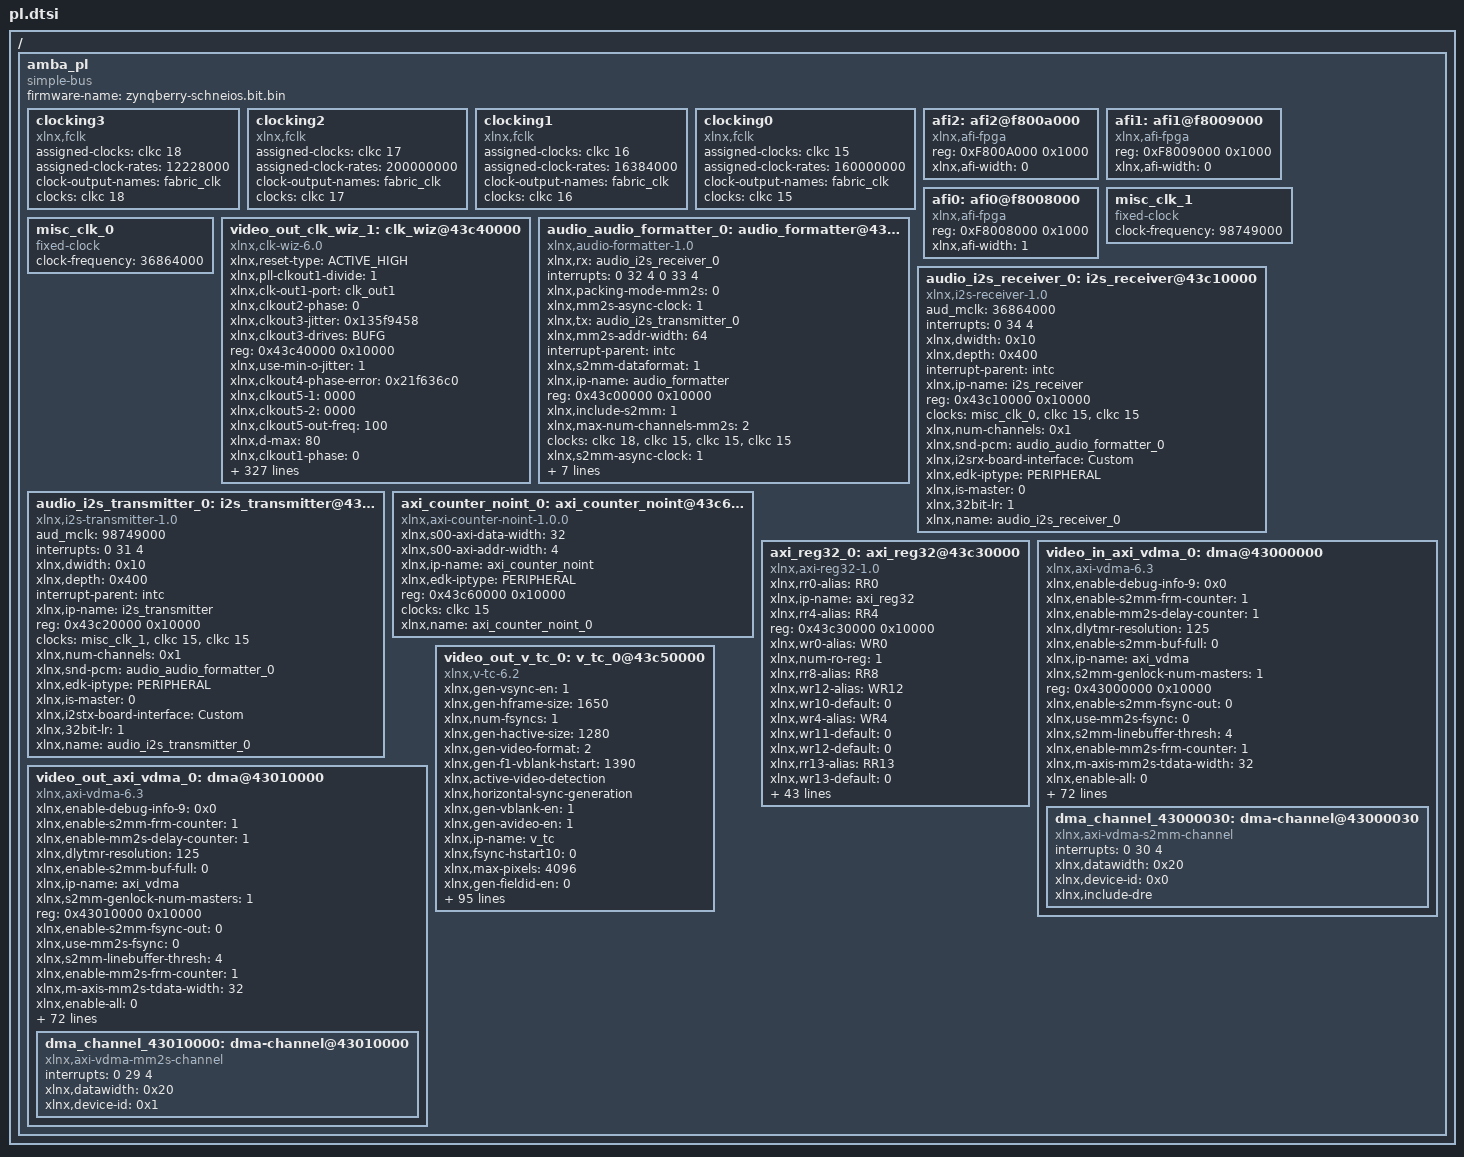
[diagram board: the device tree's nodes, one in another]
/ {
	amba_pl: amba_pl {
		ranges;
		compatible = "simple-bus";
		#address-cells = <1>;
		#size-cells = <1>;
		firmware-name = "zynqberry-schneios.bit.bin";
		clocking3: clocking3 {
			compatible = "xlnx,fclk";
			assigned-clocks = <&clkc 18>;
			assigned-clock-rates = <12228000>;
			#clock-cells = <0>;
			clock-output-names = "fabric_clk";
			clocks = <&clkc 18>;
		};
		clocking2: clocking2 {
			compatible = "xlnx,fclk";
			assigned-clocks = <&clkc 17>;
			assigned-clock-rates = <200000000>;
			#clock-cells = <0>;
			clock-output-names = "fabric_clk";
			clocks = <&clkc 17>;
		};
		clocking1: clocking1 {
			compatible = "xlnx,fclk";
			assigned-clocks = <&clkc 16>;
			assigned-clock-rates = <16384000>;
			#clock-cells = <0>;
			clock-output-names = "fabric_clk";
			clocks = <&clkc 16>;
		};
		clocking0: clocking0 {
			compatible = "xlnx,fclk";
			assigned-clocks = <&clkc 15>;
			assigned-clock-rates = <160000000>;
			#clock-cells = <0>;
			clock-output-names = "fabric_clk";
			clocks = <&clkc 15>;
		};
		afi2: afi2@f800a000 {
			status = "okay";
			compatible = "xlnx,afi-fpga";
			#address-cells = <1>;
			reg = <0xF800A000 0x1000>;
			#size-cells = <0>;
			xlnx,afi-width = <0>;
		};
		afi1: afi1@f8009000 {
			status = "okay";
			compatible = "xlnx,afi-fpga";
			#address-cells = <1>;
			reg = <0xF8009000 0x1000>;
			#size-cells = <0>;
			xlnx,afi-width = <0>;
		};
		afi0: afi0@f8008000 {
			status = "okay";
			compatible = "xlnx,afi-fpga";
			#address-cells = <1>;
			reg = <0xF8008000 0x1000>;
			#size-cells = <0>;
			xlnx,afi-width = <1>;
		};
		misc_clk_1: misc_clk_1 {
			compatible = "fixed-clock";
			clock-frequency = <98749000>;
			#clock-cells = <0>;
		};
		misc_clk_0: misc_clk_0 {
			compatible = "fixed-clock";
			clock-frequency = <36864000>;
			#clock-cells = <0>;
		};
		video_out_clk_wiz_1: clk_wiz@43c40000 {
			xlnx,reset-type = "ACTIVE_HIGH";
			xlnx,pll-clkout1-divide = <1>;
			xlnx,clk-out1-port = "clk_out1";
			xlnx,clkout2-phase = <0>;
			xlnx,clkout3-jitter = <0x135f9458>;
			xlnx,clkout3-drives = "BUFG";
			reg = <0x43c40000 0x10000>;
			xlnx,use-min-o-jitter = <1>;
			xlnx,clkout4-phase-error = <0x21f636c0>;
			xlnx,clkout5-1 = <0000>;
			xlnx,clkout5-2 = <0000>;
			xlnx,clkout5-out-freq = <100>;
			xlnx,d-max = <80>;
			xlnx,clkout1-phase = <0>;
			xlnx,divide6-auto = <0x186a0>;
			xlnx,clkout1-jitter = <0x13dd8e58>;
			xlnx,clkfb-in-n-port = "clkfb_in_n";
			xlnx,clkout2-requested-out-freq = <0x1620d350>;
			xlnx,use-locked = <1>;
			xlnx,pll-clkout5-duty-cycle = <0x7a120>;
			xlnx,mmcm-clkout3-use-fine-ps;
			xlnx,clkout1-drives = "BUFG";
			xlnx,input-clk-stopped-port = "input_clk_stopped";
			xlnx,clkout4-duty-cycle = <50>;
			xlnx,divide3-auto = <0x186a0>;
			xlnx,use-dyn-reconfig = <1>;
			xlnx,clkout3-actual-freq = <100>;
			xlnx,clkout6-requested-duty-cycle = <50>;
			xlnx,diff-clk-in1-board-interface = "Custom";
			xlnx,mmcm-clkout0-duty-cycle = <0x7a120>;
			xlnx,clkin2-jitter-ps = <100>;
			xlnx,clkout2-1 = <0000>;
			xlnx,in-freq-units = "Units_MHz";
			xlnx,clkout2-2 = <0000>;
			xlnx,feedback-source = "FDBK_AUTO";
			xlnx,clkout5-requested-out-freq = <100>;
			xlnx,name = "video_out_clk_wiz_1";
			xlnx,prim-in-freq = <200>;
			xlnx,mmcm-clkout5-divide = <1>;
			xlnx,clkout3-phase-error = <0x21f636c0>;
			xlnx,clk-in2-board-interface = "Custom";
			xlnx,clkin1-ui-jitter = <0x2710>;
			xlnx,use-inclk-switchover = <0>;
			clock-names = "clk_in1" , "s_axi_aclk";
			xlnx,clkout5-duty-cycle = <50>;
			xlnx,use-clkout4-bar = <0>;
			xlnx,mmcm-clkout1-duty-cycle = <0x7a120>;
			xlnx,mmcm-clkout2-use-fine-ps;
			xlnx,clkout2-out-freq = <0x1620d350>;
			xlnx,use-dyn-phase-shift = <0>;
			xlnx,mmcm-clkout3-divide = <1>;
			xlnx,clkout2-actual-freq = <100>;
			xlnx,o-min = <1>;
			xlnx,daddr-port = "daddr";
			xlnx,precision = <1>;
			xlnx,mmcm-ref-jitter1 = <0x2710>;
			clock-output-names = "0x43c40000-clk_out1 0x43c40000-clk_out2";
			xlnx,mmcm-ref-jitter2 = <0x2710>;
			xlnx,pll-notes = "No , notes";
			xlnx,use-phase-alignment = <1>;
			xlnx,ref-clk-freq = <100>;
			xlnx,clkout7-requested-duty-cycle = <50>;
			xlnx,inclk-sum-row0 = "Input , Clock , Freq , (MHz) , Input , Jitter , (UI)";
			xlnx,inclk-sum-row1 = "__primary_________200.000____________0.010";
			xlnx,use-fast-simulation = <0>;
			xlnx,inclk-sum-row2 = "no_secondary_input_clock";
			xlnx,mmcm-clkout1-divide = <2>;
			xlnx,din-port = "din";
			xlnx,reset-board-interface = "Custom";
			xlnx,clkout6-duty-cycle = <50>;
			xlnx,clkout2-phase-error = <0x134092d8>;
			xlnx,clkout1-requested-duty-cycle = <50>;
			xlnx,vco-max = <1200>;
			xlnx,use-freq-synth = <1>;
			xlnx,primtype-sel = "AUTO";
			xlnx,mmcm-clkout2-duty-cycle = <0x7a120>;
			xlnx,clkout5-used = <0>;
			xlnx,d-min = <1>;
			xlnx,pll-clkfbout-mult = <1>;
			xlnx,mmcm-clkout4-cascade;
			xlnx,use-clkout1-bar = <0>;
			xlnx,clk-out6-port = "clk_out6";
			xlnx,clkout2-sequence-number = <1>;
			xlnx,clk-valid-port = "CLK_VALID";
			xlnx,clkout2-used = <1>;
			xlnx,clkout4-sequence-number = <1>;
			xlnx,psincdec-port = "psincdec";
			xlnx,mmcm-clkout1-use-fine-ps;
			xlnx,clk-out3-port = "clk_out3";
			xlnx,clkout6-sequence-number = <1>;
			xlnx,platform = "UNKNOWN";
			xlnx,mmcm-clkout6-phase = <0>;
			xlnx,clkout1-actual-freq = <0x1620d350>;
			xlnx,clkout6-out-freq = <100>;
			xlnx,nr-outputs = <2>;
			xlnx,mmcm-clkin2-period = <10>;
			xlnx,prim-in-jitter = <0x2710>;
			xlnx,mmcm-clkfbout-mult-f = <0x2367b88>;
			status = "okay";
			xlnx,clkout6-1 = <0000>;
			xlnx,clkout6-2 = <0000>;
			xlnx,clkout7-duty-cycle = <50>;
			xlnx,outclk-sum-row1 = "clk_out1__74.25000______0.000______50.0______333.287____322.999";
			xlnx,outclk-sum-row2 = "clk_out2__371.25000______0.000______50.0______256.477____322.999";
			xlnx,jitter-sel = "Min_O_Jitter";
			xlnx,outclk-sum-row3 = "no_CLK_OUT3_output";
			xlnx,mmcm-clkout5-phase = <0>;
			xlnx,mmcm-clkout3-duty-cycle = <0x7a120>;
			xlnx,outclk-sum-row4 = "no_CLK_OUT4_output";
			xlnx,clkfb-in-p-port = "clkfb_in_p";
			xlnx,outclk-sum-row5 = "no_CLK_OUT5_output";
			xlnx,outclk-sum-row6 = "no_CLK_OUT6_output";
			xlnx,outclk-sum-row7 = "no_CLK_OUT7_output";
			xlnx,clkout1-phase-error = <0x134092d8>;
			xlnx,divide5-auto = <0x186a0>;
			xlnx,pll-bandwidth = "OPTIMIZED";
			xlnx,psdone-port = "psdone";
			xlnx,clkout3-1 = <0000>;
			xlnx,edk-iptype = "PERIPHERAL";
			xlnx,clkout3-2 = <0000>;
			xlnx,clkout3-requested-out-freq = <100>;
			xlnx,pll-clkout4-divide = <1>;
			xlnx,pll-clkfbout-phase = <0>;
			xlnx,divide2-auto = <0x30d40>;
			xlnx,override-mmcm = <0>;
			xlnx,clkout6-jitter = <0>;
			xlnx,ss-mode = "CENTER_HIGH";
			xlnx,mmcm-notes = "None";
			xlnx,clkout6-drives = "BUFG";
			xlnx,mmcm-clkfbout-use-fine-ps;
			xlnx,mmcm-clkout0-use-fine-ps;
			xlnx,ss-mod-period = <4000>;
			xlnx,mmcm-clkout4-phase = <0>;
			xlnx,clkout2-requested-duty-cycle = <50>;
			xlnx,clkout0-actual-freq = <0x46cf710>;
			xlnx,divclk = <0000>;
			xlnx,primary-port = "clk_in1";
			xlnx,mmcm-compensation = "ZHOLD";
			xlnx,clkout6-requested-out-freq = <100>;
			xlnx,clkout0-1 = <0000>;
			xlnx,clkout0-2 = <0000>;
			xlnx,clkout2-requested-phase = <0>;
			xlnx,relative-inclk = "REL_PRIMARY";
			xlnx,pll-clkout2-divide = <1>;
			xlnx,clkout4-requested-phase = <0>;
			xlnx,enable-user-clock0 = <0>;
			xlnx,filter-1 = <0000>;
			xlnx,mmcm-clkout4-duty-cycle = <0x7a120>;
			xlnx,clkout3-out-freq = <100>;
			xlnx,clkout4-jitter = <0x15490920>;
			xlnx,clkout6-requested-phase = <0>;
			xlnx,clkoutphy-requested-freq = <600>;
			xlnx,enable-user-clock1 = <0>;
			xlnx,filter-2 = <0000>;
			xlnx,ss-mod-freq = <250>;
			xlnx,in-jitter-units = "Units_UI";
			xlnx,mmcm-divclk-divide = <10>;
			xlnx,enable-user-clock2 = <0>;
			xlnx,enable-user-clock3 = <0>;
			xlnx,lock-1 = <0000>;
			xlnx,clkout4-drives = "BUFG";
			xlnx,lock-2 = <0000>;
			xlnx,den-port = "den";
			xlnx,lock-3 = <0000>;
			xlnx,use-safe-clock-startup = <0>;
			xlnx,mmcm-clkout3-phase = <0>;
			xlnx,dwe-port = "dwe";
			xlnx,clkfb-out-n-port = "clkfb_out_n";
			xlnx,use-max-i-jitter = <0>;
			xlnx,drdy-port = "drdy";
			xlnx,vco-min = <600>;
			xlnx,pll-clkout0-divide = <1>;
			xlnx,clkin1-jitter-ps = <50>;
			xlnx,clk-in-sel-port = "clk_in_sel";
			xlnx,use-freeze = <0>;
			xlnx,clkout2-jitter = <0xf498747>;
			xlnx,enable-pll0 = <0>;
			xlnx,enable-pll1 = <0>;
			xlnx,clkout2-drives = "BUFG";
			xlnx,use-inclk-stopped = <0>;
			xlnx,use-clkout3-bar = <0>;
			xlnx,use-clk-valid = <0>;
			xlnx,mmcm-clkout2-phase = <0>;
			compatible = "xlnx,clk-wiz-6.0" , "xlnx,clocking-wizard";
			xlnx,reset-port = "reset";
			xlnx,mmcm-clkout5-duty-cycle = <0x7a120>;
			xlnx,mmcm-clkout0-divide-f = <10>;
			xlnx,pll-clkout0-duty-cycle = <0x7a120>;
			xlnx,speed-grade = <1>;
			xlnx,diff-clk-in2-board-interface = "Custom";
			xlnx,clkout3-requested-duty-cycle = <50>;
			xlnx,use-status = <0>;
			xlnx,prim-source = "Single_ended_clock_capable_pin";
			xlnx,clkout7-used = <0>;
			xlnx,use-clkfb-stopped = <0>;
			xlnx,mmcm-clkout1-phase = <0>;
			xlnx,mmcm-clkout6-divide = <1>;
			xlnx,clkout7-out-freq = <100>;
			xlnx,prim-in-timeperiod = <10>;
			xlnx,clkout4-used = <0>;
			xlnx,pll-clkin-period = <1>;
			xlnx,clk-out5-port = "clk_out5";
			xlnx,psclk-port = "psclk";
			xlnx,primitive = "MMCM";
			xlnx,clkout1-used;
			xlnx,reset-low = <0>;
			xlnx,clk-in1-board-interface = "Custom";
			xlnx,clk-out2-port = "clk_out2";
			xlnx,power-down-port = "power_down";
			xlnx,clkout7-phase-error = <0>;
			xlnx,mmcm-clkout6-duty-cycle = <0x7a120>;
			xlnx,mmcm-clkout4-divide = <1>;
			xlnx,mmcm-clkfbout-phase = <0>;
			xlnx,mmcm-clkout0-phase = <0>;
			xlnx,pll-clkout1-duty-cycle = <0x7a120>;
			xlnx,user-clk-freq0 = <100>;
			xlnx,user-clk-freq1 = <100>;
			xlnx,pll-clkout5-phase = <0>;
			xlnx,user-clk-freq2 = <100>;
			xlnx,secondary-in-jitter = <0x2710>;
			xlnx,user-clk-freq3 = <100>;
			xlnx,use-clock-sequencing = <0>;
			xlnx,secondary-source = "Single_ended_clock_capable_pin";
			xlnx,cddcdone-port = "cddcdone";
			xlnx,clkout7-phase = <0>;
			xlnx,psen-port = "psen";
			xlnx,mmcm-clkout6-use-fine-ps;
			xlnx,dclk-port = "dclk";
			xlnx,m-max = <64>;
			xlnx,outclk-sum-row0a = "Output , Output , Phase , Duty , Cycle , Pk-to-Pk , Phase";
			xlnx,clkout1-requested-out-freq = <0x46cf710>;
			xlnx,clkout6-actual-freq = <100>;
			xlnx,divide7-auto = <0x186a0>;
			xlnx,outclk-sum-row0b = "Clock , Freq , (MHz) , (degrees) , (%) , Jitter , (ps) , Error , (ps)";
			xlnx,clkout4-1 = <0000>;
			xlnx,locked-port = "locked";
			xlnx,clkin2-ui-jitter = <0x2710>;
			xlnx,clkout4-2 = <0000>;
			xlnx,enable-clock-monitor = <0>;
			xlnx,mmcm-clkout2-divide = <1>;
			xlnx,ss-mod-time = <0xfa0>;
			xlnx,auto-primitive = "MMCM";
			xlnx,divide4-auto = <0x186a0>;
			xlnx,pll-clkout4-phase = <0>;
			xlnx,use-power-down = <0>;
			xlnx,mmcm-startup-wait;
			xlnx,divide1-auto = <1>;
			xlnx,clkout4-requested-duty-cycle = <50>;
			xlnx,clkout4-requested-out-freq = <100>;
			xlnx,optimize-clocking-structure-en = <0>;
			xlnx,clkout4-out-freq = <100>;
			xlnx,clkout6-phase = <0>;
			xlnx,num-out-clks = <2>;
			xlnx,ip-name = "clk_wiz";
			xlnx,pll-clkout2-duty-cycle = <0x7a120>;
			xlnx,clkout1-1 = <0000>;
			xlnx,clkout1-2 = <0000>;
			xlnx,clkout1-duty-cycle = <50>;
			xlnx,pll-divclk-divide = <1>;
			xlnx,clkout6-phase-error = <0>;
			xlnx,dout-port = "dout";
			xlnx,clkout1-sequence-number = <1>;
			xlnx,pll-clkout3-phase = <0>;
			xlnx,cddcreq-port = "cddcreq";
			xlnx,clkout7-requested-out-freq = <100>;
			xlnx,use-spread-spectrum = <0>;
			xlnx,clkout3-sequence-number = <1>;
			xlnx,clkout5-sequence-number = <1>;
			xlnx,summary-strings = "empty";
			xlnx,pll-compensation = "SYSTEM_SYNCHRONOUS";
			xlnx,clkout5-phase = <0>;
			xlnx,clkout7-sequence-number = <1>;
			xlnx,status-port = "STATUS";
			xlnx,clkfb-out-p-port = "clkfb_out_p";
			xlnx,mmcm-clkout5-use-fine-ps;
			xlnx,clkfb-in-port = "clkfb_in";
			xlnx,clkout5-actual-freq = <100>;
			xlnx,input-mode = "frequency";
			xlnx,interface-selection = <1>;
			xlnx,mmcm-bandwidth = "HIGH";
			xlnx,calc-done = "empty";
			xlnx,pll-clkout2-phase = <0>;
			xlnx,has-cddc = <0>;
			xlnx,power-reg = <0000>;
			xlnx,mmcm-clkin1-period = <5>;
			xlnx,pll-clkout3-duty-cycle = <0x7a120>;
			xlnx,clkout2-duty-cycle = <50>;
			xlnx,clkout4-phase = <0>;
			xlnx,pll-clkout5-divide = <1>;
			xlnx,clkout7-jitter = <0>;
			clocks = <&clkc 17>, <&clkc 15>;
			xlnx,clkout1-out-freq = <0x46cf710>;
			xlnx,clkout7-drives = "BUFG";
			xlnx,clkout5-phase-error = <0>;
			xlnx,pll-clkout1-phase = <0>;
			xlnx,clkout5-requested-duty-cycle = <50>;
			xlnx,clkfb-in-signaling = "SINGLE";
			xlnx,enable-clkoutphy = <0>;
			xlnx,use-clkout2-bar = <0>;
			xlnx,secondary-port = "clk_in2";
			xlnx,clkout3-phase = <0>;
			xlnx,pll-clkout3-divide = <1>;
			xlnx,use-reset = <1>;
			xlnx,override-pll = <0>;
			xlnx,clkoutphy-mode = "VCO";
			xlnx,mmcm-clkout4-use-fine-ps;
			xlnx,clkout5-jitter = <0>;
			xlnx,clkout6-used = <0>;
			xlnx,m-min = <2>;
			xlnx,mmcm-clock-hold;
			xlnx,clkfb-stopped-port = "clkfb_stopped";
			xlnx,clk-out7-port = "clk_out7";
			xlnx,clkout1-requested-phase = <0>;
			xlnx,clkout4-actual-freq = <100>;
			xlnx,pll-clk-feedback = "CLKFBOUT";
			xlnx,phaseshift-mode = "WAVEFORM";
			xlnx,clkfb-out-port = "clkfb_out";
			xlnx,clkout5-drives = "BUFG";
			xlnx,o-max = <128>;
			xlnx,clkout3-requested-phase = <0>;
			xlnx,jitter-options = "UI";
			xlnx,secondary-in-timeperiod = <10>;
			xlnx,pll-clkout4-duty-cycle = <0x7a120>;
			xlnx,clkout3-used = <0>;
			xlnx,clkout5-requested-phase = <0>;
			xlnx,pll-clkout0-phase = <0>;
			xlnx,clk-out4-port = "clk_out4";
			xlnx,clkout3-duty-cycle = <50>;
			xlnx,clkout7-requested-phase = <0>;
			xlnx,secondary-in-freq = <100>;
			xlnx,use-min-power = <0>;
			xlnx,clkfbout-1 = <0000>;
			#clock-cells = <1>;
			xlnx,pll-ref-jitter = <0x2710>;
			xlnx,clkfbout-2 = <0000>;
			xlnx,component-name = "zsys_clk_wiz_1_0";
		};
		audio_audio_formatter_0: audio_formatter@43c00000 {
			xlnx,rx = <&audio_i2s_receiver_0>;
			interrupts = < 0 32 4 0 33 4 >;
			compatible = "xlnx,audio-formatter-1.0" , "xlnx,audio-formatter-1.0";
			xlnx,packing-mode-mm2s = <0>;
			xlnx,mm2s-async-clock = <1>;
			xlnx,tx = <&audio_i2s_transmitter_0>;
			xlnx,mm2s-addr-width = <64>;
			interrupt-parent = <&intc>;
			xlnx,s2mm-dataformat = <1>;
			xlnx,ip-name = "audio_formatter";
			reg = <0x43c00000 0x10000>;
			xlnx,include-s2mm = <1>;
			xlnx,max-num-channels-mm2s = <2>;
			clocks = <&clkc 18>, <&clkc 15>, <&clkc 15>, <&clkc 15>;
			xlnx,s2mm-async-clock = <1>;
			xlnx,packing-mode-s2mm = <0>;
			xlnx,edk-iptype = "PERIPHERAL";
			xlnx,s2mm-addr-width = <64>;
			status = "okay";
			clock-names = "aud_mclk" , "m_axis_mm2s_aclk" , "s_axi_lite_aclk" , "s_axis_s2mm_aclk";
			xlnx,mm2s-dataformat = <3>;
			interrupt-names = "irq_mm2s" , "irq_s2mm";
			xlnx,include-mm2s = <1>;
			xlnx,max-num-channels-s2mm = <2>;
			xlnx,name = "audio_audio_formatter_0";
		};
		audio_i2s_receiver_0: i2s_receiver@43c10000 {
			aud_mclk = <36864000>;
			interrupts = < 0 34 4 >;
			compatible = "xlnx,i2s-receiver-1.0" , "xlnx,i2s-receiver-1.0";
			xlnx,dwidth = <0x10>;
			xlnx,depth = <0x400>;
			interrupt-parent = <&intc>;
			xlnx,ip-name = "i2s_receiver";
			reg = <0x43c10000 0x10000>;
			clocks = <&misc_clk_0>, <&clkc 15>, <&clkc 15>;
			xlnx,num-channels = <0x1>;
			xlnx,snd-pcm = <&audio_audio_formatter_0>;
			xlnx,i2srx-board-interface = "Custom";
			xlnx,edk-iptype = "PERIPHERAL";
			xlnx,is-master = <0>;
			status = "okay";
			clock-names = "aud_mclk" , "m_axis_aud_aclk" , "s_axi_ctrl_aclk";
			xlnx,32bit-lr = <1>;
			interrupt-names = "irq";
			xlnx,name = "audio_i2s_receiver_0";
		};
		audio_i2s_transmitter_0: i2s_transmitter@43c20000 {
			aud_mclk = <98749000>;
			interrupts = < 0 31 4 >;
			compatible = "xlnx,i2s-transmitter-1.0" , "xlnx,i2s-transmitter-1.0";
			xlnx,dwidth = <0x10>;
			xlnx,depth = <0x400>;
			interrupt-parent = <&intc>;
			xlnx,ip-name = "i2s_transmitter";
			reg = <0x43c20000 0x10000>;
			clocks = <&misc_clk_1>, <&clkc 15>, <&clkc 15>;
			xlnx,num-channels = <0x1>;
			xlnx,snd-pcm = <&audio_audio_formatter_0>;
			xlnx,edk-iptype = "PERIPHERAL";
			xlnx,is-master = <0>;
			xlnx,i2stx-board-interface = "Custom";
			status = "okay";
			clock-names = "aud_mclk" , "s_axi_ctrl_aclk" , "s_axis_aud_aclk";
			xlnx,32bit-lr = <1>;
			interrupt-names = "irq";
			xlnx,name = "audio_i2s_transmitter_0";
		};
		axi_counter_noint_0: axi_counter_noint@43c60000 {
			xlnx,s00-axi-data-width = <32>;
			compatible = "xlnx,axi-counter-noint-1.0.0";
			status = "okay";
			clock-names = "s00_axi_aclk";
			xlnx,s00-axi-addr-width = <4>;
			xlnx,ip-name = "axi_counter_noint";
			xlnx,edk-iptype = "PERIPHERAL";
			reg = <0x43c60000 0x10000>;
			clocks = <&clkc 15>;
			xlnx,name = "axi_counter_noint_0";
		};
		axi_reg32_0: axi_reg32@43c30000 {
			xlnx,rr0-alias = "RR0";
			xlnx,ip-name = "axi_reg32";
			xlnx,rr4-alias = "RR4";
			reg = <0x43c30000 0x10000>;
			xlnx,wr0-alias = "WR0";
			xlnx,num-ro-reg = <1>;
			xlnx,rr8-alias = "RR8";
			xlnx,wr12-alias = "WR12";
			xlnx,wr10-default = <0>;
			xlnx,wr4-alias = "WR4";
			xlnx,wr11-default = <0>;
			xlnx,wr12-default = <0>;
			xlnx,rr13-alias = "RR13";
			xlnx,wr13-default = <0>;
			xlnx,wr8-alias = "WR8";
			xlnx,wr14-default = <0>;
			xlnx,wr15-default = <0>;
			compatible = "xlnx,axi-reg32-1.0";
			xlnx,rr3-alias = "RR3";
			xlnx,rr7-alias = "RR7";
			xlnx,wr11-alias = "WR11";
			xlnx,wr0-default = <0>;
			xlnx,wr3-alias = "WR3";
			xlnx,wr1-default = <0>;
			xlnx,wr2-default = <0>;
			xlnx,rr12-alias = "RR12";
			status = "okay";
			xlnx,wr15-alias = "WR15";
			xlnx,wr3-default = <0>;
			xlnx,wr7-alias = "WR7";
			xlnx,wr4-default = <0>;
			xlnx,wr5-default = <0>;
			xlnx,wr6-default = <0>;
			xlnx,name = "axi_reg32_0";
			xlnx,wr7-default = <0>;
			xlnx,wr8-default = <0>;
			xlnx,wr9-default = <0>;
			xlnx,rr2-alias = "RR2";
			clocks = <&clkc 15>;
			xlnx,rr6-alias = "RR6";
			xlnx,wr10-alias = "WR10";
			xlnx,wr2-alias = "WR2";
			xlnx,edk-iptype = "PERIPHERAL";
			xlnx,rr11-alias = "RR11";
			xlnx,wr14-alias = "WR14";
			xlnx,wr-readable;
			xlnx,wr6-alias = "WR6";
			clock-names = "s_axi_aclk";
			xlnx,rr15-alias = "RR15";
			xlnx,rr1-alias = "RR1";
			xlnx,rr5-alias = "RR5";
			xlnx,num-wr-reg = <1>;
			xlnx,wr1-alias = "WR1";
			xlnx,reg-width = <32>;
			xlnx,rr10-alias = "RR10";
			xlnx,rr9-alias = "RR9";
			xlnx,wr13-alias = "WR13";
			xlnx,wr5-alias = "WR5";
			xlnx,rr14-alias = "RR14";
			xlnx,wr9-alias = "WR9";
		};
		video_in_axi_vdma_0: dma@43000000 {
			xlnx,enable-debug-info-9 = <0x0>;
			xlnx,enable-s2mm-frm-counter = <1>;
			xlnx,enable-mm2s-delay-counter = <1>;
			xlnx,dlytmr-resolution = <125>;
			xlnx,enable-s2mm-buf-full = <0>;
			xlnx,ip-name = "axi_vdma";
			xlnx,s2mm-genlock-num-masters = <1>;
			reg = <0x43000000 0x10000>;
			xlnx,enable-s2mm-fsync-out = <0>;
			xlnx,use-mm2s-fsync = <0>;
			xlnx,s2mm-linebuffer-thresh = <4>;
			xlnx,enable-mm2s-frm-counter = <1>;
			xlnx,m-axis-mm2s-tdata-width = <32>;
			xlnx,enable-all = <0>;
			xlnx,dynamic-resolution = <1>;
			xlnx,enable-s2mm-rst-out = <0>;
			interrupt-names = "s2mm_introut";
			xlnx,s2mm-sof-enable = <0x1>;
			xlnx,mm2s-genlock-num-masters = <1>;
			xlnx,enable-mm2s-fsync-out = <0>;
			xlnx,mm2s-linebuffer-thresh = <4>;
			compatible = "xlnx,axi-vdma-6.3" , "xlnx,axi-vdma-1.00.a";
			xlnx,enable-tstvec = <0>;
			interrupt-parent = <&intc>;
			xlnx,s2mm-max-burst-length = <32>;
			xlnx,enable-mm2s-rst-out = <0>;
			xlnx,mm2s-sof-enable = <1>;
			xlnx,include-s2mm-dre = <0x1>;
			xlnx,enable-s2mm-frmstr-reg = <0>;
			xlnx,m-axi-s2mm-data-width = <64>;
			xlnx,enable-s2mm-sts-reg = <0>;
			xlnx,mm2s-max-burst-length = <8>;
			status = "okay";
			xlnx,include-mm2s-dre = <0x0>;
			xlnx,name = "video_in_axi_vdma_0";
			xlnx,enable-mm2s-frmstr-reg = <0>;
			interrupts = < 0 30 4 >;
			xlnx,m-axi-mm2s-data-width = <64>;
			xlnx,flush-on-fsync = <0x1>;
			xlnx,include-s2mm-sf = <1>;
			xlnx,single-interface = <0>;
			xlnx,s2mm-linebuffer-depth = <0x1000>;
			xlnx,include-s2mm = <0x1>;
			xlnx,addr-width = <32>;
			clocks = <&clkc 15>, <&clkc 15>, <&clkc 15>;
			xlnx,s-axis-s2mm-tdata-width = <32>;
			xlnx,enable-debug-info-10 = <0>;
			xlnx,addrwidth = <0x20>;
			xlnx,enable-debug-info-11 = <0>;
			xlnx,edk-iptype = "PERIPHERAL";
			xlnx,enable-debug-info-12 = <0>;
			xlnx,use-fsync = <1>;
			xlnx,s2mm-genlock-repeat-en = <1>;
			xlnx,enable-debug-info-13 = <0x0>;
			xlnx,enable-vert-flip = <0x0>;
			xlnx,include-mm2s-sf = <0>;
			xlnx,enable-debug-info-14 = <0x1>;
			xlnx,include-internal-genlock = <0x1>;
			clock-names = "m_axi_s2mm_aclk" , "s_axi_lite_aclk" , "s_axis_s2mm_aclk";
			xlnx,enable-debug-info-15 = <0x1>;
			xlnx,mm2s-linebuffer-depth = <0x200>;
			xlnx,include-mm2s = <0x0>;
			xlnx,s2mm-genlock-mode = <0x0>;
			xlnx,flush-fsync = <0x1>;
			xlnx,select-xpm = <0>;
			xlnx,s2mm-data-width = <0x40>;
			xlnx,num-fstores = <0x1>;
			xlnx,enable-s2mm-param-updt = <0>;
			xlnx,enable-vidparam-reads = <0x1>;
			xlnx,mm2s-genlock-repeat-en = <0>;
			xlnx,prmry-is-aclk-async = <0>;
			xlnx,s2mm-tdata-width = <0x20>;
			#dma-cells = <1>;
			xlnx,enable-vidprmtr-reads = <1>;
			xlnx,mm2s-genlock-mode = <0x0>;
			xlnx,enable-debug-info-0 = <0>;
			xlnx,enable-debug-all = <0x0>;
			xlnx,enable-debug-info-1 = <0x0>;
			xlnx,mm2s-data-width = <0x40>;
			xlnx,enable-debug-info-2 = <0>;
			xlnx,enable-mm2s-param-updt = <0>;
			xlnx,enable-debug-info-3 = <0>;
			xlnx,enable-s2mm-delay-counter = <1>;
			xlnx,enable-debug-info-4 = <0>;
			xlnx,enable-debug-info-5 = <0x0>;
			xlnx,mm2s-tdata-width = <0x20>;
			xlnx,enable-debug-info-6 = <0x1>;
			xlnx,enable-debug-info-7 = <0x1>;
			xlnx,use-s2mm-fsync = <2>;
			xlnx,enable-debug-info-8 = <0>;
			xlnx,enable-mm2s-buf-empty = <0>;
			dma_channel_43000030: dma-channel@43000030 {
				interrupts = < 0 30 4 >;
				xlnx,datawidth = <0x20>;
				xlnx,device-id = <0x0>;
				compatible = "xlnx,axi-vdma-s2mm-channel";
				xlnx,include-dre;
			};
		};
		video_out_axi_vdma_0: dma@43010000 {
			xlnx,enable-debug-info-9 = <0x0>;
			xlnx,enable-s2mm-frm-counter = <1>;
			xlnx,enable-mm2s-delay-counter = <1>;
			xlnx,dlytmr-resolution = <125>;
			xlnx,enable-s2mm-buf-full = <0>;
			xlnx,ip-name = "axi_vdma";
			xlnx,s2mm-genlock-num-masters = <1>;
			reg = <0x43010000 0x10000>;
			xlnx,enable-s2mm-fsync-out = <0>;
			xlnx,use-mm2s-fsync = <0>;
			xlnx,s2mm-linebuffer-thresh = <4>;
			xlnx,enable-mm2s-frm-counter = <1>;
			xlnx,m-axis-mm2s-tdata-width = <32>;
			xlnx,enable-all = <0>;
			xlnx,dynamic-resolution = <1>;
			xlnx,enable-s2mm-rst-out = <0>;
			interrupt-names = "mm2s_introut";
			xlnx,s2mm-sof-enable = <0x1>;
			xlnx,mm2s-genlock-num-masters = <1>;
			xlnx,enable-mm2s-fsync-out = <0>;
			xlnx,mm2s-linebuffer-thresh = <4>;
			compatible = "xlnx,axi-vdma-6.3" , "xlnx,axi-vdma-1.00.a";
			xlnx,enable-tstvec = <0>;
			interrupt-parent = <&intc>;
			xlnx,s2mm-max-burst-length = <8>;
			xlnx,enable-mm2s-rst-out = <0>;
			xlnx,mm2s-sof-enable = <1>;
			xlnx,include-s2mm-dre = <0x0>;
			xlnx,enable-s2mm-frmstr-reg = <0>;
			xlnx,m-axi-s2mm-data-width = <64>;
			xlnx,enable-s2mm-sts-reg = <0>;
			xlnx,mm2s-max-burst-length = <16>;
			status = "okay";
			xlnx,include-mm2s-dre = <0x0>;
			xlnx,name = "video_out_axi_vdma_0";
			xlnx,enable-mm2s-frmstr-reg = <0>;
			interrupts = < 0 29 4 >;
			xlnx,m-axi-mm2s-data-width = <32>;
			xlnx,flush-on-fsync = <0x1>;
			xlnx,include-s2mm-sf = <1>;
			xlnx,single-interface = <0>;
			xlnx,s2mm-linebuffer-depth = <0x200>;
			xlnx,include-s2mm = <0x0>;
			xlnx,addr-width = <32>;
			clocks = <&clkc 15>, <&clkc 15>, <&clkc 15>;
			xlnx,s-axis-s2mm-tdata-width = <32>;
			xlnx,enable-debug-info-10 = <0>;
			xlnx,addrwidth = <0x20>;
			xlnx,enable-debug-info-11 = <0>;
			xlnx,edk-iptype = "PERIPHERAL";
			xlnx,enable-debug-info-12 = <0>;
			xlnx,use-fsync = <1>;
			xlnx,s2mm-genlock-repeat-en = <1>;
			xlnx,enable-debug-info-13 = <0x0>;
			xlnx,enable-vert-flip = <0x0>;
			xlnx,include-mm2s-sf = <0>;
			xlnx,enable-debug-info-14 = <0x1>;
			xlnx,include-internal-genlock = <0x1>;
			clock-names = "m_axi_mm2s_aclk" , "m_axis_mm2s_aclk" , "s_axi_lite_aclk";
			xlnx,enable-debug-info-15 = <0x1>;
			xlnx,mm2s-linebuffer-depth = <0x400>;
			xlnx,include-mm2s = <0x1>;
			xlnx,s2mm-genlock-mode = <0x0>;
			xlnx,flush-fsync = <0x1>;
			xlnx,select-xpm = <0>;
			xlnx,s2mm-data-width = <0x40>;
			xlnx,num-fstores = <0x1>;
			xlnx,enable-s2mm-param-updt = <0>;
			xlnx,enable-vidparam-reads = <0x1>;
			xlnx,mm2s-genlock-repeat-en = <0>;
			xlnx,prmry-is-aclk-async = <0>;
			xlnx,s2mm-tdata-width = <0x20>;
			#dma-cells = <1>;
			xlnx,enable-vidprmtr-reads = <1>;
			xlnx,mm2s-genlock-mode = <0x0>;
			xlnx,enable-debug-info-0 = <0>;
			xlnx,enable-debug-all = <0x0>;
			xlnx,enable-debug-info-1 = <0x0>;
			xlnx,mm2s-data-width = <0x20>;
			xlnx,enable-debug-info-2 = <0>;
			xlnx,enable-mm2s-param-updt = <0>;
			xlnx,enable-debug-info-3 = <0>;
			xlnx,enable-s2mm-delay-counter = <1>;
			xlnx,enable-debug-info-4 = <0>;
			xlnx,enable-debug-info-5 = <0x0>;
			xlnx,mm2s-tdata-width = <0x20>;
			xlnx,enable-debug-info-6 = <0x1>;
			xlnx,enable-debug-info-7 = <0x1>;
			xlnx,use-s2mm-fsync = <2>;
			xlnx,enable-debug-info-8 = <0>;
			xlnx,enable-mm2s-buf-empty = <0>;
			dma_channel_43010000: dma-channel@43010000 {
				interrupts = < 0 29 4 >;
				xlnx,datawidth = <0x20>;
				xlnx,device-id = <0x1>;
				compatible = "xlnx,axi-vdma-mm2s-channel";
			};
		};
		video_out_v_tc_0: v_tc_0@43c50000 {
			xlnx,gen-vsync-en = <1>;
			xlnx,gen-hframe-size = <1650>;
			xlnx,num-fsyncs = <1>;
			xlnx,gen-hactive-size = <1280>;
			xlnx,gen-video-format = <2>;
			xlnx,gen-f1-vblank-hstart = <1390>;
			xlnx,active-video-detection;
			xlnx,horizontal-sync-generation;
			xlnx,gen-vblank-en = <1>;
			xlnx,gen-avideo-en = <1>;
			xlnx,ip-name = "v_tc";
			xlnx,fsync-hstart10 = <0>;
			xlnx,max-pixels = <4096>;
			xlnx,gen-fieldid-en = <0>;
			reg = <0x43c50000 0x10000>;
			xlnx,det-vblank-en = <1>;
			xlnx,fsync-hstart11 = <0>;
			xlnx,fsync-hstart12 = <0>;
			xlnx,pixels-per-clock = <0x4>;
			xlnx,gen-interlaced = <0>;
			xlnx,det-avideo-en = <1>;
			xlnx,fsync-hstart13 = <0>;
			xlnx,fsync-hstart14 = <0>;
			xlnx,gen-f0-vblank-hend = <1390>;
			xlnx,fsync-hstart15 = <0>;
			xlnx,det-hsync-en = <1>;
			xlnx,enable-generation;
			xlnx,gen-avideo-polarity = <1>;
			xlnx,max-lines-per-frame = <2048>;
			xlnx,has-axi4-lite = <1>;
			compatible = "xlnx,v-tc-6.2" , "xlnx,bridge-v-tc-6.1";
			xlnx,max-clocks-per-line = <4096>;
			xlnx,gen-f0-vframe-size = <750>;
			xlnx,gen-f0-vblank-hstart = <1390>;
			xlnx,max-lines = <2048>;
			xlnx,gen-f0-vsync-vstart = <724>;
			xlnx,horizontal-blank-generation;
			xlnx,gen-hsync-end = <1430>;
			xlnx,gen-f0-vsync-hstart = <1390>;
			xlnx,gen-f1-vsync-hend = <1390>;
			xlnx,vertical-blank-detection;
			xlnx,gen-vsync-polarity = <1>;
			xlnx,fsync-vstart0 = <0>;
			xlnx,gen-hsync-polarity = <1>;
			xlnx,fsync-vstart1 = <0>;
			status = "okay";
			xlnx,fsync-vstart2 = <0>;
			xlnx,gen-hsync-start = <1390>;
			xlnx,gen-f0-vsync-vend = <729>;
			xlnx,fsync-vstart3 = <0>;
			xlnx,vertical-sync-detection;
			xlnx,frame-syncs = <1>;
			xlnx,fsync-vstart4 = <0>;
			xlnx,gen-vactive-size = <720>;
			xlnx,name = "video_out_v_tc_0";
			xlnx,fsync-vstart5 = <0>;
			xlnx,gen-achroma-en = <0>;
			xlnx,fsync-vstart6 = <0>;
			xlnx,det-fieldid-en = <0>;
			xlnx,fsync-vstart7 = <0>;
			xlnx,gen-hsync-en = <1>;
			xlnx,fsync-vstart8 = <0>;
			xlnx,fsync-vstart10 = <0>;
			xlnx,fsync-vstart9 = <0>;
			xlnx,fsync-vstart11 = <0>;
			xlnx,arbitrary-res-en = /bits/ 8 <0x0>;
			xlnx,fsync-vstart12 = <0>;
			xlnx,fsync-vstart13 = <0>;
			clocks = <&video_out_clk_wiz_1 0>, <&clkc 15>;
			xlnx,fsync-vstart14 = <0>;
			xlnx,fsync-vstart15 = <0>;
			xlnx,gen-cparity = <0>;
			xlnx,edk-iptype = "PERIPHERAL";
			xlnx,vertical-sync-generation;
			xlnx,gen-f1-vblank-hend = <1390>;
			xlnx,det-vsync-en = <1>;
			xlnx,gen-vblank-polarity = <1>;
			xlnx,fsync-hstart0 = <0>;
			clock-names = "clk" , "s_axi_aclk";
			xlnx,interlace-en = <0>;
			xlnx,gen-auto-switch = <0>;
			xlnx,fsync-hstart1 = <0>;
			xlnx,fsync-hstart2 = <0>;
			xlnx,active-video-generation;
			xlnx,fsync-hstart3 = <0>;
			xlnx,fsync-hstart4 = <0>;
			xlnx,horizontal-blank-detection;
			xlnx,fsync-hstart5 = <0>;
			xlnx,gen-f1-vframe-size = <750>;
			xlnx,fsync-hstart6 = <0>;
			xlnx,fsync-hstart7 = <0>;
			xlnx,fsync-hstart8 = <0>;
			xlnx,gen-hblank-en = <1>;
			xlnx,fsync-hstart9 = <0>;
			xlnx,horizontal-sync-detection;
			xlnx,gen-f1-vsync-vend = <729>;
			xlnx,detect-en = <0>;
			xlnx,det-hblank-en = <1>;
			xlnx,vid-ppc = <4>;
			xlnx,has-intc-if = <0>;
			xlnx,generate-en = <1>;
			xlnx,gen-achroma-polarity = <1>;
			xlnx,sync-en = <0>;
			xlnx,det-achroma-en = <0>;
			xlnx,generator;
			xlnx,gen-f1-vsync-vstart = <724>;
			xlnx,vertical-blank-generation;
			xlnx,gen-hblank-polarity = <1>;
			xlnx,video-mode = "720p";
			xlnx,gen-fieldid-polarity = <1>;
			xlnx,gen-f1-vsync-hstart = <1390>;
			xlnx,gen-f0-vsync-hend = <1390>;
		};
	};
};
